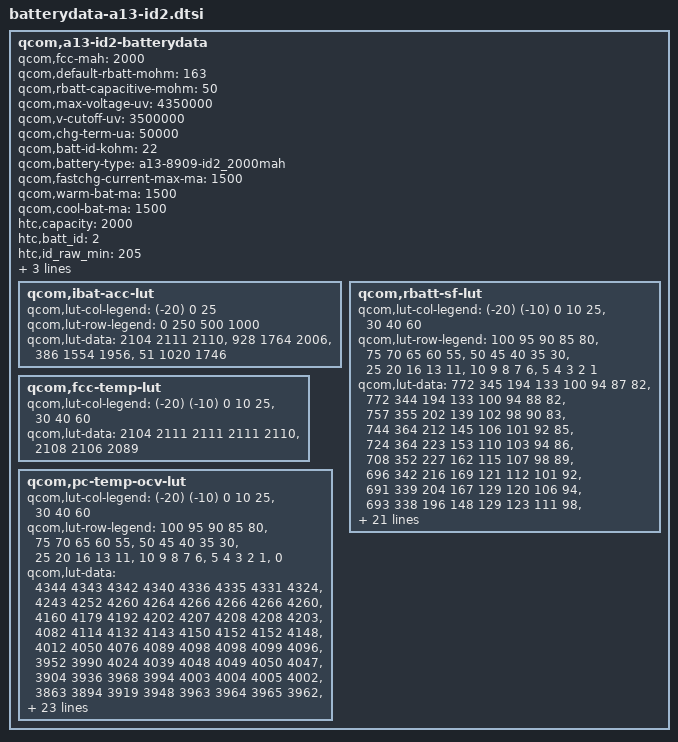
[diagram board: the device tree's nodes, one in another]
/* Copyright (c) 2013, The Linux Foundation. All rights reserved.
 *
 * This program is free software; you can redistribute it and/or modify
 * it under the terms of the GNU General Public License version 2 and
 * only version 2 as published by the Free Software Foundation.
 *
 * This program is distributed in the hope that it will be useful,
 * but WITHOUT ANY WARRANTY; without even the implied warranty of
 * MERCHANTABILITY or FITNESS FOR A PARTICULAR PURPOSE.  See the
 * GNU General Public License for more details.
 */

qcom,a13-id2-batterydata {
	qcom,fcc-mah = <2000>;
	qcom,default-rbatt-mohm = <163>;
	qcom,rbatt-capacitive-mohm = <50>;
	qcom,max-voltage-uv = <4350000>;
	qcom,v-cutoff-uv = <3500000>;
	qcom,chg-term-ua = <50000>;
	qcom,batt-id-kohm = <22>;
	qcom,battery-type = "a13-8909-id2_2000mah";
        qcom,fastchg-current-max-ma = <1500>;
        qcom,warm-bat-ma = <1500>;
        qcom,cool-bat-ma = <1500>;
	htc,capacity = <2000>;
	htc,batt_id = <2>;
	htc,id_raw_min = <205>;
	htc,id_raw_max = <385>;
	htc,type = <1>;
	htc,model_name = "B0PM3100";

	qcom,ibat-acc-lut {
		qcom,lut-col-legend = <(-20) 0 25>;
		qcom,lut-row-legend = <0 250 500 1000>;
		qcom,lut-data = <2104 2111 2110>,
				<928 1764 2006>,
				<386 1554 1956>,
				<51 1020 1746>;
	};

	qcom,rbatt-sf-lut {
		qcom,lut-col-legend = <(-20) (-10) 0 10 25>,
				<30 40 60>;
		qcom,lut-row-legend = <100 95 90 85 80>,
				<75 70 65 60 55>,
				<50 45 40 35 30>,
				<25 20 16 13 11>,
				<10 9 8 7 6>,
				<5 4 3 2 1>;
		qcom,lut-data = <772 345 194 133 100 94 87 82>,
				<772 344 194 133 100 94 88 82>,
				<757 355 202 139 102 98 90 83>,
				<744 364 212 145 106 101 92 85>,
				<724 364 223 153 110 103 94 86>,
				<708 352 227 162 115 107 98 89>,
				<696 342 216 169 121 112 101 92>,
				<691 339 204 167 129 120 106 94>,
				<693 338 196 148 129 123 111 98>,
				<701 339 195 137 112 108 102 93>,
				<723 340 194 134 102 96 90 85>,
				<766 342 196 136 102 98 91 87>,
				<836 350 199 139 104 99 94 90>,
				<960 369 208 140 107 101 97 93>,
				<1163 421 222 147 109 102 94 89>,
				<1395 582 241 158 109 101 91 86>,
				<1854 890 274 161 106 98 91 87>,
				<2477 1050 361 160 106 99 91 86>,
				<3039 1137 477 162 99 94 87 83>,
				<4144 1298 637 185 104 97 90 86>,
				<4944 1400 733 208 107 100 92 87>,
				<5986 1638 836 244 110 103 94 89>,
				<7401 1975 937 296 115 106 96 90>,
				<9201 2390 1052 374 120 109 99 92>,
				<11915 2950 1171 466 125 112 100 92>,
				<15596 3734 1318 566 126 112 96 88>,
				<21393 4909 1623 679 128 111 97 91>,
				<33301 6768 2164 821 140 118 102 93>,
				<52087 9944 3094 1028 163 129 109 98>,
				<83427 15762 4811 1477 212 156 134 115>;
	};

	qcom,fcc-temp-lut {
		qcom,lut-col-legend = <(-20) (-10) 0 10 25>,
				<30 40 60>;
		qcom,lut-data = <2104 2111 2111 2111 2110>,
				<2108 2106 2089>;
	};

	qcom,pc-temp-ocv-lut {
		qcom,lut-col-legend = <(-20) (-10) 0 10 25>,
				<30 40 60>;
		qcom,lut-row-legend = <100 95 90 85 80>,
				<75 70 65 60 55>,
				<50 45 40 35 30>,
				<25 20 16 13 11>,
				<10 9 8 7 6>,
				<5 4 3 2 1>,
				<0>;
		qcom,lut-data = <4344 4343 4342 4340 4336 4335 4331 4324>,
				<4243 4252 4260 4264 4266 4266 4266 4260>,
				<4160 4179 4192 4202 4207 4208 4208 4203>,
				<4082 4114 4132 4143 4150 4152 4152 4148>,
				<4012 4050 4076 4089 4098 4098 4099 4096>,
				<3952 3990 4024 4039 4048 4049 4050 4047>,
				<3904 3936 3968 3994 4003 4004 4005 4002>,
				<3863 3894 3919 3948 3963 3964 3965 3962>,
				<3829 3858 3879 3899 3920 3923 3926 3924>,
				<3801 3829 3847 3859 3874 3876 3880 3880>,
				<3780 3802 3820 3830 3838 3839 3841 3841>,
				<3764 3780 3798 3807 3814 3816 3818 3818>,
				<3749 3762 3780 3789 3796 3797 3799 3799>,
				<3734 3746 3768 3775 3781 3782 3783 3783>,
				<3719 3730 3758 3764 3770 3769 3768 3762>,
				<3700 3713 3742 3755 3756 3754 3750 3738>,
				<3678 3695 3716 3733 3735 3733 3728 3716>,
				<3652 3682 3685 3700 3706 3705 3701 3688>,
				<3623 3670 3668 3674 3679 3678 3676 3665>,
				<3598 3660 3660 3665 3673 3673 3671 3662>,
				<3583 3654 3656 3660 3670 3671 3669 3660>,
				<3566 3647 3651 3656 3667 3668 3667 3659>,
				<3544 3638 3646 3651 3663 3665 3664 3656>,
				<3517 3626 3641 3646 3658 3660 3660 3652>,
				<3484 3610 3632 3638 3649 3651 3651 3638>,
				<3439 3588 3612 3620 3626 3627 3625 3606>,
				<3378 3556 3577 3581 3580 3578 3575 3556>,
				<3298 3510 3523 3522 3516 3514 3513 3491>,
				<3216 3438 3444 3442 3432 3428 3422 3402>,
				<3145 3322 3324 3319 3302 3296 3285 3261>,
				<3000 3000 3000 3000 3000 3000 3000 3000>;
	};
};
